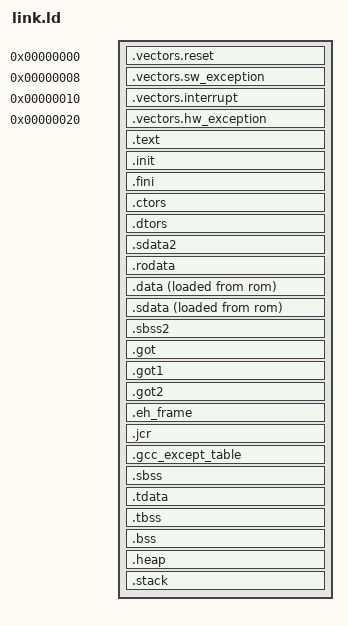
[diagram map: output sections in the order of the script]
/*******************************************************************/
/*                                                                 */
/* This file is automatically generated by linker script generator.*/
/*                                                                 */
/* Version:                                 */
/*                                                                 */
/* Copyright (c) 2010 Xilinx, Inc.  All rights reserved.           */
/*                                                                 */
/* Description : MicroBlaze Linker Script                          */
/*                                                                 */
/*******************************************************************/



_STACK_SIZE = DEFINED(_STACK_SIZE) ? _STACK_SIZE : ${STACK_SIZE};
_HEAP_SIZE = DEFINED(_HEAP_SIZE) ? _HEAP_SIZE : ${HEAP_SIZE};

/* Define Memories in the system */
INCLUDE linkvar.ld;

/* Specify the default entry point to the program */

ENTRY(_start)

/* Define the sections, and where they are mapped in memory */

SECTIONS
{

.vectors.reset 0x0 : {
   KEEP (*(.vectors.reset))
} > rom

.vectors.sw_exception 0x8 : {
   KEEP (*(.vectors.sw_exception))
} > rom

.vectors.interrupt 0x10 : {
   KEEP (*(.vectors.interrupt))
} > rom

.vectors.hw_exception 0x20 : {
   KEEP (*(.vectors.hw_exception))
} > rom

.text : {
   *(.text)
   *(.text.*)
   *(.gnu.linkonce.t.*)
} > rom

.init : {
   KEEP (*(.init))
} > rom

.fini : {
   KEEP (*(.fini))
} > rom

.ctors : {
   __CTOR_LIST__ = .;
   ___CTORS_LIST___ = .;
   KEEP (*crtbegin.o(.ctors))
   KEEP (*(EXCLUDE_FILE(*crtend.o) .ctors))
   KEEP (*(SORT(.ctors.*)))
   KEEP (*(.ctors))
   __CTOR_END__ = .;
   ___CTORS_END___ = .;
} > rom

.dtors : {
   __DTOR_LIST__ = .;
   ___DTORS_LIST___ = .;
   KEEP (*crtbegin.o(.dtors))
   KEEP (*(EXCLUDE_FILE(*crtend.o) .dtors))
   KEEP (*(SORT(.dtors.*)))
   KEEP (*(.dtors))
   PROVIDE(__DTOR_END__ = .);
   PROVIDE(___DTORS_END___ = .);
} > rom

.sdata2 : {
   . = ALIGN(8);
   __sdata2_start = .;
   *(.sdata2)
   *(.sdata2.*)
   *(.gnu.linkonce.s2.*)
   . = ALIGN(8);
   __sdata2_end = .;
} > rom

.rodata : {
   __rodata_start = .;
   *(.rodata)
   *(.rodata.*)
   *(.gnu.linkonce.r.*)
   __rodata_end = .;
} > rom

.data : {
   . = ALIGN(4);
   __data_start = .;
   *(.data)
   *(.data.*)
   *(.gnu.linkonce.d.*)
   __data_end = .;
}  > ram AT > rom  /* "> ram" is the VMA, "> rom" is the LMA */

.sdata : {
   . = ALIGN(8);
   __sdata_start = .;
   *(.sdata)
   *(.sdata.*)
   *(.gnu.linkonce.s.*)
   __sdata_end = .;
} > ram AT > rom  /* "> ram" is the VMA, "> rom" is the LMA */




.sbss2 : {
   __sbss2_start = .;
   *(.sbss2)
   *(.sbss2.*)
   *(.gnu.linkonce.sb2.*)
   __sbss2_end = .;
} > ram


.got : {
   *(.got)
} > ram

.got1 : {
   *(.got1)
} > ram

.got2 : {
   *(.got2)
} > ram

.eh_frame : {
   *(.eh_frame)
} > ram

.jcr : {
   *(.jcr)
} > ram

.gcc_except_table : {
   *(.gcc_except_table)
} > rom


.sbss (NOLOAD) : {
   . = ALIGN(4);
   __sbss_start = .;
   *(.sbss)
   *(.sbss.*)
   *(.gnu.linkonce.sb.*)
   . = ALIGN(8);
   __sbss_end = .;
} > ram

.tdata : {
   __tdata_start = .;
   *(.tdata)
   *(.tdata.*)
   *(.gnu.linkonce.td.*)
   __tdata_end = .;
} > ram

.tbss : {
   __tbss_start = .;
   *(.tbss)
   *(.tbss.*)
   *(.gnu.linkonce.tb.*)
   __tbss_end = .;
} > ram

.bss (NOLOAD) : {
   . = ALIGN(4);
   __bss_start = .;
   *(.bss)
   *(.bss.*)
   *(.gnu.linkonce.b.*)
   *(COMMON)
   . = ALIGN(4);
   __bss_end = .;
} > ram

_SDA_BASE_ = __sdata_start + ((__sbss_end - __sdata_start) / 2 );

_SDA2_BASE_ = __sdata2_start + ((__sbss2_end - __sdata2_start) / 2 );

/* Generate Stack and Heap definitions */

.heap (NOLOAD) : {
   . = ALIGN(8);
   _heap = .;
   _heap_start = .;
   . += _HEAP_SIZE;
   _heap_end = .;
} > ram

.stack (NOLOAD) : {
   _stack_end = .;
   . += _STACK_SIZE;
   . = ALIGN(8);
   _stack = .;
   __stack = _stack;
} > ram

_end = .;
}
